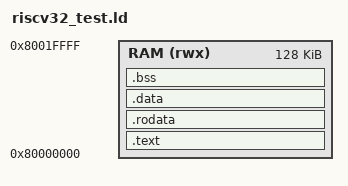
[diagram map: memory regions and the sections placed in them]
/* RISC-V 32-bit Test Linker Script for QEMU virt machine */
OUTPUT_ARCH(riscv)
ENTRY(_start)

MEMORY
{
    RAM (rwx) : ORIGIN = 0x80000000, LENGTH = 128K
}

SECTIONS
{
    .text : {
        *(.text._start)
        *(.text)
        *(.text.*)
    } > RAM

    .rodata : {
        *(.rodata)
        *(.rodata.*)
    } > RAM

    .data : {
        *(.data)
        *(.data.*)
    } > RAM

    .bss : {
        __bss_start = .;
        *(.bss)
        *(.bss.*)
        *(COMMON)
        __bss_end = .;
    } > RAM

    _end = .;
}
